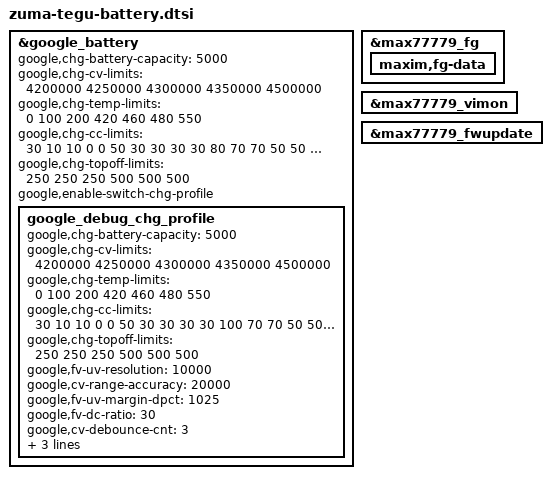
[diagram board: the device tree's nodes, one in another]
// SPDX-License-Identifier: GPL-2.0-only
/*
 * Battery device tree entries specific to tegu
 *
 * Copyright 2023 Google,LLC
 *
 */

&google_battery {
	google,chg-battery-capacity = <5000>;

	google,chg-cv-limits = <4200000 4250000 4300000 4350000 4500000>;
	google,chg-temp-limits = <0 100 200 420 460 480 550>;
	google,chg-cc-limits = <
		 30   10   10    0    0
		 50   30   30   30   30
		 80   70   70   50   50
		 80   50   50   50   50
		 50   50   50    0    0
		 30    0    0    0    0
	>;

	google,chg-topoff-limits = <250 250 250 500 500 500>;

	google,enable-switch-chg-profile;

	google_debug_chg_profile {
		google,chg-battery-capacity = <5000>;

		google,chg-cv-limits = <4200000 4250000 4300000 4350000 4500000>;
		google,chg-temp-limits = <0 100 200 420 460 480 550>;
		google,chg-cc-limits = <
			 30   10   10    0    0
			 50   30   30   30   30
			100   70   70   50   50
			 80   50   50   50   50
			 50   50   50    0    0
			 30    0    0    0    0
		>;

		google,chg-topoff-limits = <250 250 250 500 500 500>;

		google,fv-uv-resolution = <10000>;
		google,cv-range-accuracy = <20000>;
		google,fv-uv-margin-dpct = <1025>;
		google,fv-dc-ratio = <30>;
		google,cv-debounce-cnt = <3>;
		google,cv-tier-ov-cnt = <10>;
		google,cv-tier-switch-cnt = <3>;
		google,cv-otv-margin = <12000>;
	};
};

&max77779_fg {
	maxim,fg-data {
		#include "zuma-tegu-battery-data.dtsi"
	};
};

&max77779_vimon {
	status = "okay";
};

&max77779_fwupdate {
	status = "okay";
};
